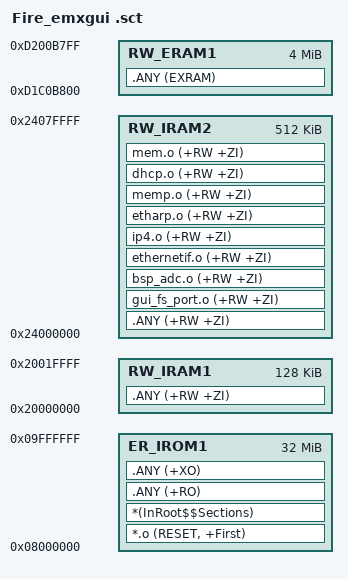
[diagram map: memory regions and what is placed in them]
; *************************************************************
; *** Scatter-Loading Description File generated by uVision ***
; *************************************************************

LR_IROM1 0x08000000 0x02000000  {    ; load region size_region
  ER_IROM1 0x08000000 0x02000000  {  ; load address = execution address
   *.o (RESET, +First)
   *(InRoot$$Sections)
   .ANY (+RO)
   .ANY (+XO)
  }
  RW_IRAM1 0x20000000 0x00020000  {  ; RW data
   .ANY (+RW +ZI)
 }
  RW_IRAM2 0x24000000 0x00080000  {
   .ANY (+RW +ZI)
   gui_fs_port.o (+RW +ZI);由于DMA访问权限,功能要正常使用的话,缓冲区要放在非TCM区中
   bsp_adc.o (+RW +ZI)
   ethernetif.o (+RW +ZI)
   ip4.o (+RW +ZI)
   etharp.o (+RW +ZI)
   memp.o (+RW +ZI)
   dhcp.o (+RW +ZI)
   mem.o (+RW +ZI)
  }  
  RW_ERAM1 (0xd18bb800+0x00350000) 0x00400000 {  ; 外部SDRAM  //100000
  ;*.o (HEAP)          选择堆区
   .ANY (EXRAM)				;选择EXRAM节区

  }
}
